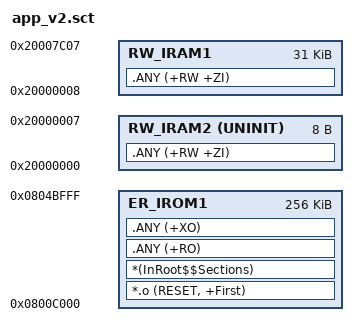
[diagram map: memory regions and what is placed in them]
; *************************************************************
; *** Scatter-Loading Description File generated by uVision ***
; *************************************************************

LR_IROM1 0x0800C000 0x00040000  {    ; load region size_region
  ER_IROM1 0x0800C000 0x00040000  {  ; load address = execution address
   *.o (RESET, +First)
   *(InRoot$$Sections)
   .ANY (+RO)
   .ANY (+XO)
  }
  RW_IRAM1 0x20000008 0x00007C00  {  ; RW data
   .ANY (+RW +ZI)
  }
  RW_IRAM2 0x20000000 UNINIT 0x00000008  {
   .ANY (+RW +ZI)
  }
}

